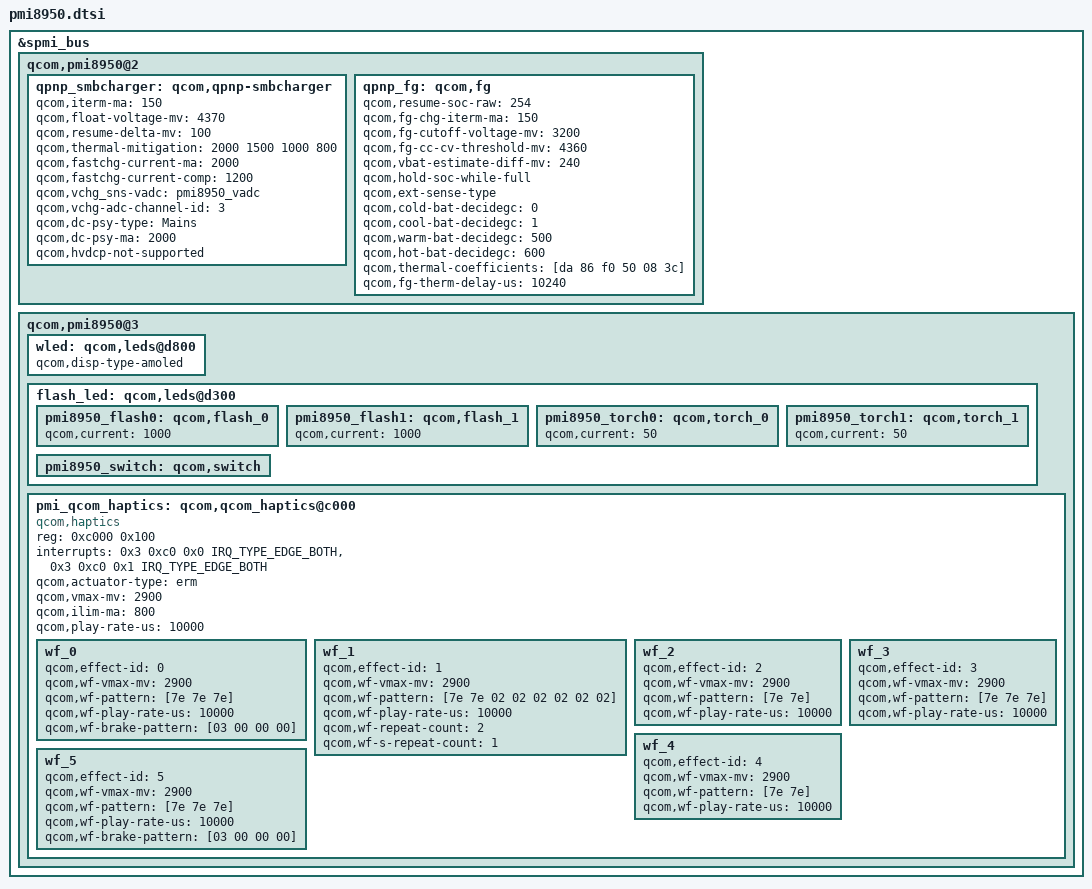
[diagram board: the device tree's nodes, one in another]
/* Copyright (c) 2015-2018, The Linux Foundation. All rights reserved.
 *
 * This program is free software; you can redistribute it and/or modify
 * it under the terms of the GNU General Public License version 2 and
 * only version 2 as published by the Free Software Foundation.
 *
 * This program is distributed in the hope that it will be useful,
 * but WITHOUT ANY WARRANTY; without even the implied warranty of
 * MERCHANTABILITY or FITNESS FOR A PARTICULAR PURPOSE.  See the
 * GNU General Public License for more details.
 */

#include "../pmi8950.dtsi"

&spmi_bus {
	qcom,pmi8950@2 {
		qpnp_smbcharger: qcom,qpnp-smbcharger {
			/delete-property/ qcom,chg-inhibit-fg;
			/delete-property/ qcom,parallel-usb-min-current-ma;
			/delete-property/ qcom,parallel-usb-9v-min-current-ma;
			/delete-property/ qcom,parallel-allowed-lowering-ma;

			qcom,iterm-ma = <150>;
			qcom,float-voltage-mv = <4370>;
			qcom,resume-delta-mv = <100>;
			qcom,thermal-mitigation = <2000 1500 1000 800>;
			qcom,fastchg-current-ma = <2000>;
			qcom,fastchg-current-comp = <1200>;
			qcom,vchg_sns-vadc = <&pmi8950_vadc>;
			qcom,vchg-adc-channel-id = <3>;
			qcom,dc-psy-type = "Mains";
			qcom,dc-psy-ma = <2000>;
			qcom,hvdcp-not-supported;
		};

		qpnp_fg: qcom,fg {
			/* Battery */
			/delete-property/ qcom,resume-soc;
			qcom,resume-soc-raw = <254>;
			qcom,fg-chg-iterm-ma = <150>;
			qcom,fg-cutoff-voltage-mv = <3200>;
			qcom,fg-cc-cv-threshold-mv = <4360>;
			qcom,vbat-estimate-diff-mv = <240>;
			qcom,hold-soc-while-full;

			/* Thermals */
			qcom,ext-sense-type;
			qcom,cold-bat-decidegc = <0>;
			qcom,cool-bat-decidegc = <1>;
			qcom,warm-bat-decidegc = <500>;
			qcom,hot-bat-decidegc = <600>;
			qcom,thermal-coefficients = [da 86 f0 50 08 3c];
			qcom,fg-therm-delay-us = <10240>;
		};
	};

	qcom,pmi8950@3 {
		wled: qcom,leds@d800 {
			qcom,disp-type-amoled;
		};

		flash_led: qcom,leds@d300 {
			pmi8950_flash0: qcom,flash_0 {
				qcom,current = <1000>;
			};

			pmi8950_flash1: qcom,flash_1 {
				qcom,current = <1000>;
			};

			pmi8950_torch0: qcom,torch_0 {
				qcom,current = <50>;
			};

			pmi8950_torch1: qcom,torch_1 {
				qcom,current = <50>;
			};

			pmi8950_switch: qcom,switch {
				/delete-node/ reg0;
			};
		};

		/delete-node/ qcom,haptics@c000;
		pmi_qcom_haptics: qcom,qcom_haptics@c000 {
			status = "okay";
			compatible = "qcom,haptics";
			reg = <0xc000 0x100>;
			interrupts = <0x3 0xc0 0x0 IRQ_TYPE_EDGE_BOTH>,
					<0x3 0xc0 0x1 IRQ_TYPE_EDGE_BOTH>;
			interrupt-names = "hap-sc-irq", "hap-play-irq";
			qcom,actuator-type = "erm";
			qcom,vmax-mv = <2900>;
			qcom,ilim-ma = <800>;
			qcom,play-rate-us = <10000>;
			wf_0 {
				/* CLICK */
				qcom,effect-id = <0>;
				qcom,wf-vmax-mv = <2900>;
				qcom,wf-pattern = [7e 7e 7e];
				qcom,wf-play-rate-us = <10000>;
				qcom,wf-brake-pattern = [03 00 00 00];
			};
			wf_1 {
				/* DOUBLE CLICK */
				qcom,effect-id = <1>;
				qcom,wf-vmax-mv = <2900>;
				qcom,wf-pattern = [7e 7e 02 02 02 02 02 02];
				qcom,wf-play-rate-us = <10000>;
				qcom,wf-repeat-count = <2>;
				qcom,wf-s-repeat-count = <1>;
			};
			wf_2 {
				/* TICK */
				qcom,effect-id = <2>;
				qcom,wf-vmax-mv = <2900>;
				qcom,wf-pattern = [7e 7e];
				qcom,wf-play-rate-us = <10000>;
			};
			wf_3 {
				/* THUD */
				qcom,effect-id = <3>;
				qcom,wf-vmax-mv = <2900>;
				qcom,wf-pattern = [7e 7e 7e];
				qcom,wf-play-rate-us = <10000>;
			};
			wf_4 {
				/* POP */
				qcom,effect-id = <4>;
				qcom,wf-vmax-mv = <2900>;
				qcom,wf-pattern = [7e 7e];
				qcom,wf-play-rate-us = <10000>;
			};
			wf_5 {
				/* HEAVY CLICK */
				qcom,effect-id = <5>;
				qcom,wf-vmax-mv = <2900>;
				qcom,wf-pattern = [7e 7e 7e];
				qcom,wf-play-rate-us = <10000>;
				qcom,wf-brake-pattern = [03 00 00 00];
			};
		};
	};
};

